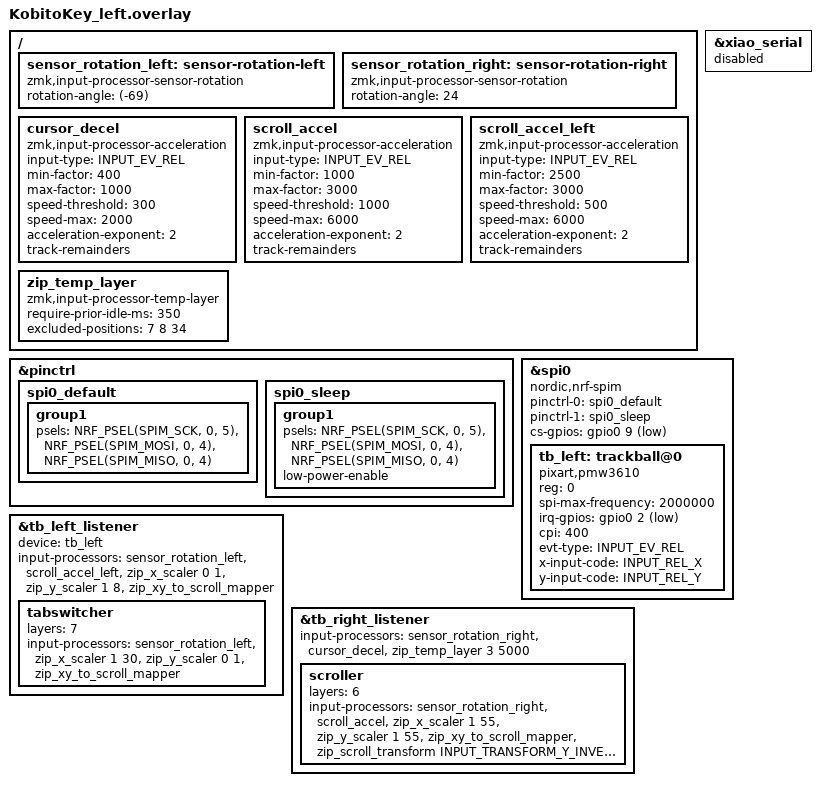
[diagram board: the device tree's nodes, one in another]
#include "kobitokey.dtsi"
#include <zephyr/dt-bindings/input/input-event-codes.h>
#include <input/processors.dtsi>
#include <input/processors/sensor_rotation.dtsi>

&xiao_serial { status = "disabled"; };

&pinctrl {
    spi0_default: spi0_default {
        group1 {
            psels = <NRF_PSEL(SPIM_SCK,  0, 5)>,
                    <NRF_PSEL(SPIM_MOSI, 0, 4)>,
                    <NRF_PSEL(SPIM_MISO, 0, 4)>;
        };
    };
    spi0_sleep: spi0_sleep {
        group1 {
            psels = <NRF_PSEL(SPIM_SCK,  0, 5)>,
                    <NRF_PSEL(SPIM_MOSI, 0, 4)>,
                    <NRF_PSEL(SPIM_MISO, 0, 4)>;
            low-power-enable;
        };
    };
};

&spi0 {
    status = "okay";
    compatible = "nordic,nrf-spim";
    pinctrl-0 = <&spi0_default>;
    pinctrl-1 = <&spi0_sleep>;
    pinctrl-names = "default", "sleep";
    cs-gpios = <&gpio0 9 GPIO_ACTIVE_LOW>;

    tb_left: trackball@0 {
        status = "okay";
        compatible = "pixart,pmw3610";
        reg = <0>;
        spi-max-frequency = <2000000>;
        irq-gpios = <&gpio0 2 (GPIO_ACTIVE_LOW | GPIO_PULL_UP)>;
        cpi = <400>; /* センサー感度: 初動取りこぼし改善のため200→400 */


        evt-type = <INPUT_EV_REL>;
        x-input-code = <INPUT_REL_X>;
        y-input-code = <INPUT_REL_Y>;
    };
};

/ {
    sensor_rotation_left: sensor-rotation-left {
        compatible = "zmk,input-processor-sensor-rotation";
        status = "okay";
        #input-processor-cells = <0>;
        rotation-angle = <(-69)>; /* -24 から 45度回転を追加 */
    };

    sensor_rotation_right: sensor-rotation-right {
        compatible = "zmk,input-processor-sensor-rotation";
        #input-processor-cells = <0>;
        status = "okay";
        rotation-angle = <24>;
    };

    /* 右トラボのカーソル用 低速自動減速プロセッサ（19mmボールの精密操作対策）。
       高速側は max-factor=1000(等倍)のままにして、OS側のポインタ加速との
       二重加速（速い動きでの暴れ）を避け、低速時のみ自動でゲインを下げる。 */
    cursor_decel: cursor_decel {
        compatible = "zmk,input-processor-acceleration";
        #input-processor-cells = <0>;
        status = "okay";
        input-type = <INPUT_EV_REL>;
        min-factor = <400>;             /* 低速時の倍率(=0.4倍、精密モード相当) */
        max-factor = <1000>;            /* 高速時の倍率(=1.0倍、現状維持で加速なし) */
        speed-threshold = <300>;        /* この速度以下は精密固定(counts/sec) */
        speed-max = <2000>;             /* この速度で通常倍率(1.0倍)に到達 */
        acceleration-exponent = <2>;    /* 1=線形 2=二次 3=三次 */
        track-remainders;               /* 端数を持ち越して滑らかに */
    };

    /* 右トラボのスクロール用 加速プロセッサ（速く動かすほど倍率が上がる） */
    scroll_accel: scroll_accel {
        compatible = "zmk,input-processor-acceleration";
        #input-processor-cells = <0>;
        status = "okay";
        input-type = <INPUT_EV_REL>;
        min-factor = <1000>;            /* 低速時の倍率(=1.0倍、減速しない) */
        max-factor = <3000>;            /* 高速時の最大倍率(=3.0倍) */
        speed-threshold = <1000>;       /* これ以上の速度で加速開始(counts/sec) */
        speed-max = <6000>;             /* この速度で最大倍率に到達 */
        acceleration-exponent = <2>;    /* 1=線形 2=二次 3=三次 */
        track-remainders;               /* 端数を持ち越して滑らかに */
    };

    /* 左トラボのスクロール用 加速プロセッサ（右と独立管理） */
    scroll_accel_left: scroll_accel_left {
        compatible = "zmk,input-processor-acceleration";
        #input-processor-cells = <0>;
        status = "okay";
        input-type = <INPUT_EV_REL>;
        min-factor = <2500>;            /* 低速時の倍率(=2.5倍)。ズレた方向でもtick閾値を越えやすくし死角を狭める */
        max-factor = <3000>;            /* 高速時の最大倍率(=3.0倍) */
        speed-threshold = <500>;        /* 加速開始を早める(counts/sec) */
        speed-max = <6000>;             /* この速度で最大倍率に到達 */
        acceleration-exponent = <2>;    /* 1=線形 2=二次 3=三次 */
        track-remainders;               /* 端数を持ち越して滑らかに */
    };
};

&tb_left_listener {
    status = "okay";
    device = <&tb_left>;

    input-processors =
            <&sensor_rotation_left>,
            <&scroll_accel_left>, /* 速く動かすほど速くスクロール（左用・独立設定） */
            <&zip_x_scaler 0 1>,  /* X(横)を無効化＝横スクロール出さない */
            <&zip_y_scaler 1 8>,  /* Y(縦)を縦スクロールに使用。÷15→÷8でゲインを上げ許容範囲を拡大 */
            <&zip_xy_to_scroll_mapper>;

    /* tabswitchレイヤー(7)がアクティブな間だけ、左トラボの左右movementで
       水平スクロール(WheelLeft/WheelRight)を出す。PC側でCtrl+Tab等に変換して使う。 */
    tabswitcher {
        layers = <7>;
        input-processors =
            <&sensor_rotation_left>,
            <&zip_x_scaler 1 30>, /* 左右movement→水平スクロール */
            <&zip_y_scaler 0 1>,  /* 上下movementは無効化 */
            <&zip_xy_to_scroll_mapper>;
    };
};

/ {
  /omit-if-no-ref/ zip_temp_layer: zip_temp_layer {
    compatible = "zmk,input-processor-temp-layer";
    #input-processor-cells = <2>;
    require-prior-idle-ms = <350>; /* キー押下後、何msオートマウスレイヤに入らないようにするか、誤爆防止 */
  };
};

&tb_right_listener {
    status = "okay";

    input-processors =
        <&sensor_rotation_right>,
        <&cursor_decel>, /* 低速時のみ自動で精密モード(0.4倍)になり、高速時は通常通り(1.0倍) */
        <&zip_temp_layer 3 5000>; /* オートマウスレイヤーの指定とトラボ操作及びマウスボタン押下後に滞留する時間 */

    /* scrollレイヤー(6)がアクティブな間だけ、右トラボを縦スクロール動作にする。
       layerが一致するとprocess-next無しのためbaseプロセッサ(カーソル/オートマウス)はスキップされる。 */
    scroller {
        layers = <6>;
        input-processors =
            <&sensor_rotation_right>,
            <&scroll_accel>,          /* 速く動かすほど速くスクロール（加速） */
            <&zip_x_scaler 1 55>,     /* 横スクロール有効。CPI 1200に合わせ除数55でスクロール速度維持 */
            <&zip_y_scaler 1 55>,     /* 縦スクロール速度（同上） */
            <&zip_xy_to_scroll_mapper>,
            <&zip_scroll_transform INPUT_TRANSFORM_Y_INVERT>; /* スクロール方向を反転 */
    };
};

&zip_temp_layer {
    excluded-positions = <
        7
        8
        34
    >;
};
